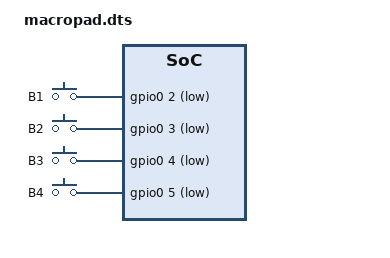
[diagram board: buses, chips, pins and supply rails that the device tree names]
// Device Tree Source for the custom macropad
/dts-v1/;
/ {
    compatible = "zmk,macropad";

    chosen {
        zmk,keyboard = &macropad;
    };

    macros {
        compatible = "zmk,macros";
    };

    buttons {
        compatible = "zmk,buttons";
        b1: button_1 {
            gpios = <&gpio0 2 GPIO_ACTIVE_LOW>; // Update pin to match SuperMini nRF52840
            label = "B1";
        };
        b2: button_2 {
            gpios = <&gpio0 3 GPIO_ACTIVE_LOW>; // Update pin to match SuperMini nRF52840
            label = "B2";
        };
        b3: button_3 {
            gpios = <&gpio0 4 GPIO_ACTIVE_LOW>; // Update pin to match SuperMini nRF52840
            label = "B3";
        };
        b4: button_4 {
            gpios = <&gpio0 5 GPIO_ACTIVE_LOW>; // Update pin to match SuperMini nRF52840
            label = "B4";
        };
    };

    encoder {
        compatible = "zmk,encoder";
        ec11 {
            gpios = <&gpio0 6 GPIO_ACTIVE_LOW>, <&gpio0 7 GPIO_ACTIVE_LOW>; // Update pins to match SuperMini nRF52840
            label = "EC11";
        };
    };
};
